AUTOSAR XML (schema 00048)
package /ComponentTypes
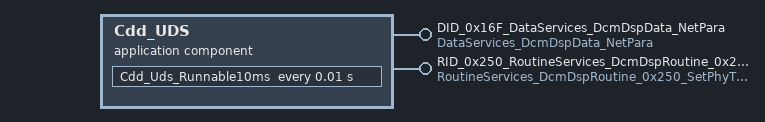
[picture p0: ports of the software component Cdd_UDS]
  application sw component type Cdd_UDS
    provide port DID_0x16F_DataServices_DcmDspData_NetPara: provided-interface=DataServices_DcmDspData_NetPara
      provided-com-specs:
        operation=WriteData, queue-length=1
        operation=ConditionCheckRead, queue-length=1
        operation=ReadData, queue-length=1
    provide port RID_0x250_RoutineServices_DcmDspRoutine_0x250_SetPhyTxMode: provided-com-specs=[{operation=RequestResults, queue-length=1}, {operation=Start, queue-length=1}], provided-interface=RoutineServices_DcmDspRoutine_0x250_SetPhyTxMode
    behavior Cdd_UDS_InternalBehavior
      init event Cdd_UDS_InitEvent: start-on-event=Cdd_UDS_Init
      timing event TMT_Cdd_Uds_Runnable10ms: start-on-event=Cdd_Uds_Runnable10ms, period=0.01
      5 x operation invoked event:
        OIT_Runnable_DID_0x16F_DataServices_DcmDspData_NetPara_ConditionCheckRead: start-on-event=DID_0x16F_DataServices_DcmDspData_NetPara_ConditionCheckRead, operation=DID_0x16F_DataServices_DcmDspData_NetPara.ConditionCheckRead
        OIT_Runnable_DID_0x16F_DataServices_DcmDspData_NetPara_ReadData: start-on-event=DID_0x16F_DataServices_DcmDspData_NetPara_ReadData, operation=DID_0x16F_DataServices_DcmDspData_NetPara.ReadData
        OIT_Runnable_DID_0x16F_DataServices_DcmDspData_NetPara_WriteData: start-on-event=DID_0x16F_DataServices_DcmDspData_NetPara_WriteData, operation=DID_0x16F_DataServices_DcmDspData_NetPara.WriteData
        OIT_Runnable_RID_0x250_RoutineServices_DcmDspRoutine_0x250_SetPhyTxMode_RequestResults: start-on-event=RID_0x250_RoutineServices_DcmDspRoutine_0x250_SetPhyTxMode_RequestResults, operation=RID_0x250_RoutineServices_DcmDspRoutine_0x250_SetPhyTxMode.RequestResults
        OIT_Runnable_RID_0x250_RoutineServices_DcmDspRoutine_0x250_SetPhyTxMode_Start: start-on-event=RID_0x250_RoutineServices_DcmDspRoutine_0x250_SetPhyTxMode_Start, operation=RID_0x250_RoutineServices_DcmDspRoutine_0x250_SetPhyTxMode.Start
      7 x runnable:
        Cdd_UDS_Init
        Cdd_Uds_Runnable10ms
        DID_0x16F_DataServices_DcmDspData_NetPara_ConditionCheckRead
        DID_0x16F_DataServices_DcmDspData_NetPara_ReadData
        DID_0x16F_DataServices_DcmDspData_NetPara_WriteData
        RID_0x250_RoutineServices_DcmDspRoutine_0x250_SetPhyTxMode_RequestResults
        RID_0x250_RoutineServices_DcmDspRoutine_0x250_SetPhyTxMode_Start
  swc implementation Cdd_UDS_Implementation: behavior=Cdd_UDS_InternalBehavior
